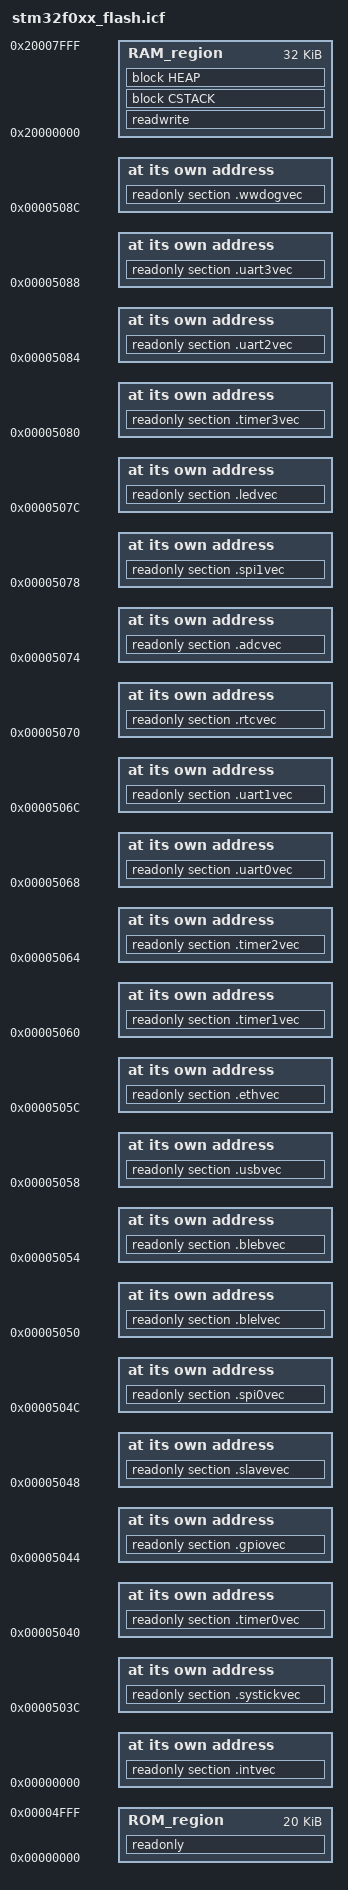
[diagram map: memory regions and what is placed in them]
/*-Specials-*/
define symbol __ICFEDIT_intvec_start__ = 0x00000000;
/*-Memory Regions-*/
define symbol __ICFEDIT_region_ROM_start__ = 0x00000000 ;
define symbol __ICFEDIT_region_ROM_end__   = 0x00004FFF;
/* do not use the first 192 bytes because this is where
 * the bootloader copies the user program vector table
 * right before it starts the user program.
 */
define symbol __ICFEDIT_region_RAM_start__ = 0x20000000;
define symbol __ICFEDIT_region_RAM_end__   = 0x20007FFF;
/*-Sizes-*/
define symbol __ICFEDIT_size_cstack__ = 0x400;
define symbol __ICFEDIT_size_heap__   = 0x200;


define memory mem with size = 4G;
define region ROM_region   = mem:[from __ICFEDIT_region_ROM_start__   to __ICFEDIT_region_ROM_end__];
define region RAM_region   = mem:[from __ICFEDIT_region_RAM_start__   to __ICFEDIT_region_RAM_end__];
export symbol __ICFEDIT_region_RAM_start__;
export symbol __ICFEDIT_region_RAM_end__;
define block CSTACK    with alignment = 8, size = __ICFEDIT_size_cstack__   { };
define block HEAP      with alignment = 8, size = __ICFEDIT_size_heap__     { };

initialize by copy { readwrite };
do not initialize  { section .noinit };

place at address mem:__ICFEDIT_intvec_start__ { readonly section .intvec };

place in ROM_region   { readonly };
place in RAM_region   { readwrite,
                        block CSTACK, block HEAP };

define symbol APP_VECTOR_SYSTICK_ADDR = 0x0000003C + 20 * 1024;
define symbol APP_VECTOR_TIMER0_ADDR = 0x00000040 + 20 * 1024;
define symbol APP_VECTOR_GPIO_ADDR = 0x00000044 + 20 * 1024;
define symbol APP_VECTOR_SLAVE_ADDR = 0x00000048 + 20 * 1024;
define symbol APP_VECTOR_SPI0_ADDR = 0x0000004C + 20 * 1024;
define symbol APP_VECTOR_BLEL_ADDR = 0x00000050 + 20 * 1024;
define symbol APP_VECTOR_BLEB_ADDR = 0x00000054 + 20 * 1024;
define symbol APP_VECTOR_USB_ADDR = 0x00000058 + 20 * 1024;
define symbol APP_VECTOR_ETH_ADDR = 0x0000005C + 20 * 1024;
define symbol APP_VECTOR_TIMER1_ADDR = 0x00000060 + 20 * 1024;
define symbol APP_VECTOR_TIMER2_ADDR = 0x00000064 + 20 * 1024;
define symbol APP_VECTOR_UART0_ADDR = 0x00000068 + 20 * 1024;
define symbol APP_VECTOR_UART1_ADDR = 0x0000006C + 20 * 1024;
define symbol APP_VECTOR_RTC_ADDR = 0x00000070 + 20 * 1024;
define symbol APP_VECTOR_ADC_ADDR = 0x00000074 + 20 * 1024;
define symbol APP_VECTOR_SPI1_ADDR = 0x00000078 + 20 * 1024;
define symbol APP_VECTOR_LED_ADDR = 0x0000007C + 20 * 1024;
define symbol APP_VECTOR_TIMER3_ADDR = 0x00000080 + 20 * 1024;
define symbol APP_VECTOR_UART2_ADDR = 0x00000084 + 20 * 1024;
define symbol APP_VECTOR_UART3_ADDR = 0x00000088 + 20 * 1024;
define symbol APP_VECTOR_WWDOG_BAT_ADDR = 0x0000008C + 20 * 1024;

place at address mem:APP_VECTOR_SYSTICK_ADDR { readonly section .systickvec};
place at address mem:APP_VECTOR_TIMER0_ADDR { readonly section .timer0vec};
place at address mem:APP_VECTOR_GPIO_ADDR { readonly section .gpiovec};
place at address mem:APP_VECTOR_SLAVE_ADDR { readonly section .slavevec};
place at address mem:APP_VECTOR_SPI0_ADDR { readonly section .spi0vec};
place at address mem:APP_VECTOR_BLEL_ADDR { readonly section .blelvec};
place at address mem:APP_VECTOR_BLEB_ADDR { readonly section .blebvec};
place at address mem:APP_VECTOR_USB_ADDR { readonly section .usbvec};
place at address mem:APP_VECTOR_ETH_ADDR { readonly section .ethvec};
place at address mem:APP_VECTOR_TIMER1_ADDR { readonly section .timer1vec};
place at address mem:APP_VECTOR_TIMER2_ADDR { readonly section .timer2vec};
place at address mem:APP_VECTOR_UART0_ADDR { readonly section .uart0vec};
place at address mem:APP_VECTOR_UART1_ADDR { readonly section .uart1vec};
place at address mem:APP_VECTOR_RTC_ADDR { readonly section .rtcvec};
place at address mem:APP_VECTOR_ADC_ADDR { readonly section .adcvec};
place at address mem:APP_VECTOR_SPI1_ADDR { readonly section .spi1vec};
place at address mem:APP_VECTOR_LED_ADDR { readonly section .ledvec};
place at address mem:APP_VECTOR_TIMER3_ADDR { readonly section .timer3vec};
place at address mem:APP_VECTOR_UART2_ADDR { readonly section .uart2vec};
place at address mem:APP_VECTOR_UART3_ADDR { readonly section .uart3vec};
place at address mem:APP_VECTOR_WWDOG_BAT_ADDR { readonly section .wwdogvec};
